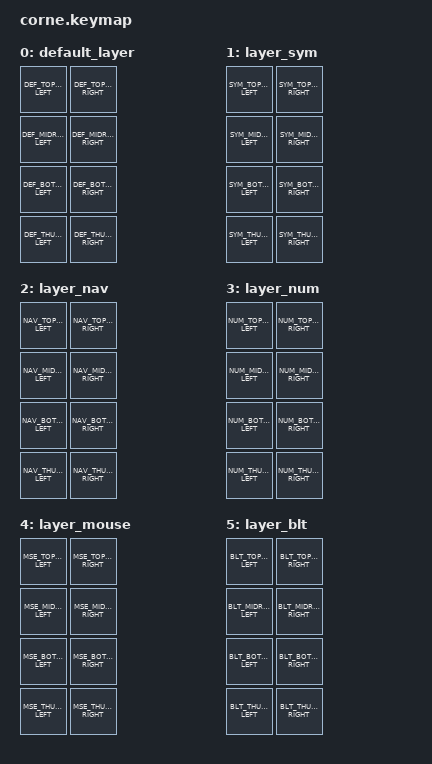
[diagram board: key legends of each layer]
/*
 * Copyright (c) 2020 The ZMK Contributors
 *
 * SPDX-License-Identifier: MIT
 */

 /* use helper macros to define left and right hand keys */
#include "zmk-helpers/key-labels/42.h"                                      // key-position labels
#define KEYS_L LT0 LT1 LT2 LT3 LT4 LM0 LM1 LM2 LM3 LM4 LB0 LB1 LB2 LB3 LB4  // left-hand keys
#define KEYS_R RT0 RT1 RT2 RT3 RT4 RM0 RM1 RM2 RM3 RM4 RB0 RB1 RB2 RB3 RB4  // right-hand keys
#define THUMBS LH2 LH1 LH0 RH0 RH1 RH2                                      // thumb keys

#include "kbd_layout/keymap.h"

#include <behaviors.dtsi>
#include <dt-bindings/zmk/keys.h>
#include <dt-bindings/zmk/bt.h>
#include <dt-bindings/zmk/mouse.h>

/ {
        behaviors {
            lhm: left_homerow_mods {
                compatible = "zmk,behavior-hold-tap";
                flavor = "balanced";
                tapping-term-ms = <500>;    // <---[[moderate duration]]
                quick-tap-ms = <0>;
                require-prior-idle-ms = <150>;
                compatible = "zmk,behavior-hold-tap";
                #binding-cells = <2>;
                bindings = <&kp>, <&kp>;
                hold-trigger-key-positions = <KEYS_R THUMBS>;
                hold-trigger-on-release;

            };
            rhm: right_homerow_mods {
                compatible = "zmk,behavior-hold-tap";
                flavor = "balanced";
                tapping-term-ms = <500>;    // <---[[moderate duration]]
                quick-tap-ms = <0>;
                require-prior-idle-ms = <150>;
                compatible = "zmk,behavior-hold-tap";
                #binding-cells = <2>;
                bindings = <&kp>, <&kp>;
                hold-trigger-key-positions = <KEYS_L THUMBS>;
                hold-trigger-on-release;
            };
            hm: homerow_mods {
                compatible = "zmk,behavior-hold-tap";
                #binding-cells = <2>;
                tapping-term-ms = <200>;    // <---[[moderate duration]]
                quick-tap-ms = <0>;
                flavor = "balanced";
                bindings = <&kp>, <&kp>;
            };
        };
        keymap {
                compatible = "zmk,keymap";

                default_layer {
                        bindings = <
           DEF_TOPROW_LEFT      DEF_TOPROW_RIGHT         
           DEF_MIDROW_LEFT      DEF_MIDROW_RIGHT         
           DEF_BOTROW_LEFT      DEF_BOTROW_RIGHT         
           DEF_THUMBS_LEFT      DEF_THUMBS_RIGHT
                        >;
                };
                layer_sym {
                        bindings = <
           SYM_TOPROW_LEFT      SYM_TOPROW_RIGHT         
           SYM_MIDROW_LEFT      SYM_MIDROW_RIGHT         
           SYM_BOTROW_LEFT      SYM_BOTROW_RIGHT         
           SYM_THUMBS_LEFT      SYM_THUMBS_RIGHT
                        >;
                };
                layer_nav {
                        bindings = <
           NAV_TOPROW_LEFT      NAV_TOPROW_RIGHT         
           NAV_MIDROW_LEFT      NAV_MIDROW_RIGHT         
           NAV_BOTROW_LEFT      NAV_BOTROW_RIGHT         
           NAV_THUMBS_LEFT      NAV_THUMBS_RIGHT
                        >;
                };
                layer_num {
                        bindings = <
           NUM_TOPROW_LEFT      NUM_TOPROW_RIGHT         
           NUM_MIDROW_LEFT      NUM_MIDROW_RIGHT         
           NUM_BOTROW_LEFT      NUM_BOTROW_RIGHT         
           NUM_THUMBS_LEFT      NUM_THUMBS_RIGHT
                        >;
                };
                layer_mouse {
                        bindings = <
           MSE_TOPROW_LEFT      MSE_TOPROW_RIGHT         
           MSE_MIDROW_LEFT      MSE_MIDROW_RIGHT         
           MSE_BOTROW_LEFT      MSE_BOTROW_RIGHT         
           MSE_THUMBS_LEFT      MSE_THUMBS_RIGHT
                        >;
                };
                layer_blt {
                        bindings = <
           BLT_TOPROW_LEFT      BLT_TOPROW_RIGHT         
           BLT_MIDROW_LEFT      BLT_MIDROW_RIGHT         
           BLT_BOTROW_LEFT      BLT_BOTROW_RIGHT         
           BLT_THUMBS_LEFT      BLT_THUMBS_RIGHT
                        >;
                };
        };
};
